VERSION ""

NS_ :

BS_:

BU_: VCU HMI

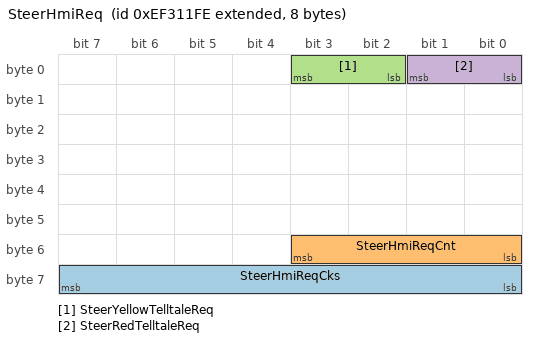
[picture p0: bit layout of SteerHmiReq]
BO_ 2398294526 SteerHmiReq: 8 VCU
 SG_ SteerHmiReqCks : 63|8@0+ (1,0) [0|255] "" Vector__XXX
 SG_ SteerHmiReqCnt : 51|4@0+ (1,0) [0|15] "" Vector__XXX
 SG_ SteerYellowTelltaleReq : 3|2@0+ (1,0) [0|3] ""  HMI
 SG_ SteerRedTelltaleReq : 1|2@0+ (1,0) [0|3] ""  HMI

CM_ BO_ 2398294526 "E2E protection: Autosar 1A
DATAID: 0x311";
CM_ SG_ 2398294526 SteerHmiReqCks "E2E CRC";
CM_ SG_ 2398294526 SteerHmiReqCnt "E2E Counter";
BA_DEF_ SG_  "SigType" ENUM  "Default","Range","RangeSigned","ASCII","Discrete","Control","ReferencePGN","DTC","StringDelimiter","StringLength","StringLengthControl","MessageCounter","MessageChecksum";
BA_DEF_ SG_  "GenSigEVName" STRING ;
BA_DEF_ SG_  "GenSigILSupport" ENUM  "No","Yes";
BA_DEF_ SG_  "GenSigSendType" ENUM  "Cyclic","OnWrite","OnWriteWithRepetition","OnChange","OnChangeWithRepetition","IfActive","IfActiveWithRepetition","NoSigSendType";
BA_DEF_ SG_  "GenSigStartValue" INT 0 2147483647;
BA_DEF_ BO_  "GenMsgILSupport" ENUM  "No","Yes";
BA_DEF_ BU_  "NmStationAddress" INT 0 255;
BA_DEF_ BO_  "GenMsgSendType" ENUM  "cyclic","NotUsed","IfActive","NotUsed","NotUsed","NotUsed","NotUsed","NotUsed","noMsgSendType";
BA_DEF_ BO_  "GenMsgRequestable" INT 0 1;
BA_DEF_ BO_  "GenMsgCycleTime" INT 0 3600000;
BA_DEF_  "DBName" STRING ;
BA_DEF_  "BusType" STRING ;
BA_DEF_  "ProtocolType" STRING ;
BA_DEF_ BO_  "VFrameFormat" ENUM  "StandardCAN","ExtendedCAN","reserved","J1939PG";
BA_DEF_DEF_  "SigType" "Default";
BA_DEF_DEF_  "GenSigEVName" "Env@Nodename_@Signame";
BA_DEF_DEF_  "GenSigILSupport" "Yes";
BA_DEF_DEF_  "GenSigSendType" "NoSigSendType";
BA_DEF_DEF_  "GenSigStartValue" 0;
BA_DEF_DEF_  "GenMsgILSupport" "Yes";
BA_DEF_DEF_  "NmStationAddress" 254;
BA_DEF_DEF_  "GenMsgSendType" "noMsgSendType";
BA_DEF_DEF_  "GenMsgRequestable" 1;
BA_DEF_DEF_  "GenMsgCycleTime" 0;
BA_DEF_DEF_  "DBName" "";
BA_DEF_DEF_  "BusType" "CAN";
BA_DEF_DEF_  "ProtocolType" "J1939";
BA_DEF_DEF_  "VFrameFormat" "J1939PG";
BA_ "DBName" "SteerHmi";
BA_ "GenMsgSendType" BO_ 2398294526 0;
BA_ "GenMsgCycleTime" BO_ 2398294526 100;
BA_ "SigType" SG_ 2398294526 SteerHmiReqCks 12;
BA_ "SigType" SG_ 2398294526 SteerHmiReqCnt 11;
BA_ "GenSigStartValue" SG_ 2398294526 SteerYellowTelltaleReq 3;
BA_ "GenSigStartValue" SG_ 2398294526 SteerRedTelltaleReq 3;
VAL_ 2398294526 SteerYellowTelltaleReq 3 "Not Available" 2 "Error" 1 "On" 0 "Off" ;
VAL_ 2398294526 SteerRedTelltaleReq 3 "Not Available" 2 "Error" 1 "On" 0 "Off" ;
